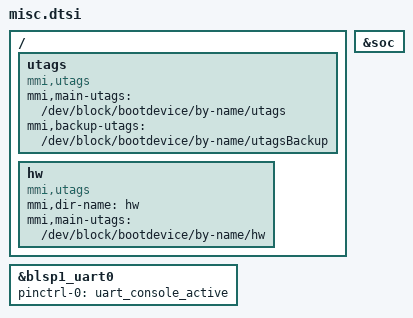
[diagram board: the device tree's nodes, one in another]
/ {
	utags {
		compatible = "mmi,utags";
		mmi,main-utags = "/dev/block/bootdevice/by-name/utags";
		mmi,backup-utags = "/dev/block/bootdevice/by-name/utagsBackup";
	};

	hw {
		compatible = "mmi,utags";
		mmi,dir-name = "hw";
		mmi,main-utags = "/dev/block/bootdevice/by-name/hw";
	};

};

&blsp1_uart0 {
	status = "ok";
	pinctrl-names = "default";
	pinctrl-0 = <&uart_console_active>;
};

&soc { 
	/delete-node/ adv7533@39;
};
